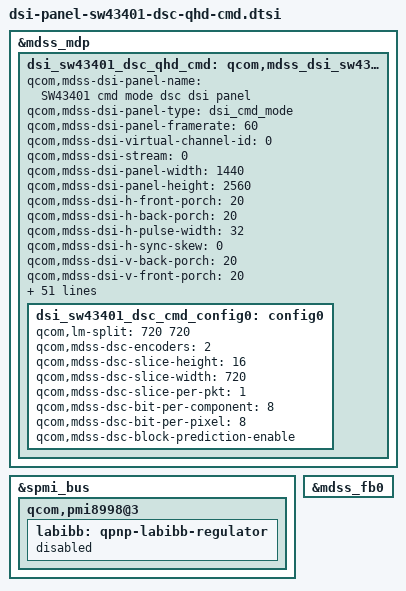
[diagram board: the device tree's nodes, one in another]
/* Copyright (c) 2017, The Linux Foundation. All rights reserved.
 *
 * This program is free software; you can redistribute it and/or modify
 * it under the terms of the GNU General Public License version 2 and
 * only version 2 as published by the Free Software Foundation.
 *
 * This program is distributed in the hope that it will be useful,
 * but WITHOUT ANY WARRANTY; without even the implied warranty of
 * MERCHANTABILITY or FITNESS FOR A PARTICULAR PURPOSE.  See the
 * GNU General Public License for more details.
 */

&mdss_mdp {
	dsi_sw43401_dsc_qhd_cmd: qcom,mdss_dsi_sw43401_dsc_qhd_cmd {
		qcom,mdss-dsi-panel-name = "SW43401 cmd mode dsc dsi panel";
		qcom,mdss-dsi-panel-type = "dsi_cmd_mode";
		qcom,mdss-dsi-panel-framerate = <60>;
		qcom,mdss-dsi-virtual-channel-id = <0>;
		qcom,mdss-dsi-stream = <0>;
		qcom,mdss-dsi-panel-width = <1440>;
		qcom,mdss-dsi-panel-height = <2560>;
		qcom,mdss-dsi-h-front-porch = <20>;
		qcom,mdss-dsi-h-back-porch = <20>;
		qcom,mdss-dsi-h-pulse-width = <32>;
		qcom,mdss-dsi-h-sync-skew = <0>;
		qcom,mdss-dsi-v-back-porch = <20>;
		qcom,mdss-dsi-v-front-porch = <20>; //180 -> 100
		qcom,mdss-dsi-v-pulse-width = <6>;
		qcom,mdss-dsi-h-left-border = <0>;
		qcom,mdss-dsi-h-right-border = <0>;
		qcom,mdss-dsi-v-top-border = <0>;
		qcom,mdss-dsi-v-bottom-border = <0>;
		qcom,mdss-dsi-bpp = <24>;
		qcom,mdss-dsi-color-order = "rgb_swap_rgb";
		qcom,mdss-dsi-underflow-color = <0xff>;
		qcom,mdss-dsi-border-color = <0>;
		qcom,mdss-dsi-h-sync-pulse = <0>;
		qcom,mdss-dsi-traffic-mode = "burst_mode";
		qcom,mdss-dsi-lane-map = "lane_map_0123";
		qcom,mdss-dsi-bllp-eof-power-mode;
		qcom,mdss-dsi-bllp-power-mode;
		/* qcom,partial-update-enabled; */
		/* qcom,panel-roi-alignment = <1440 16 1440 16 1440 16>; */
		qcom,mdss-dsi-lane-0-state;
		qcom,mdss-dsi-lane-1-state;
		qcom,mdss-dsi-lane-2-state;
		qcom,mdss-dsi-lane-3-state;
		qcom,mdss-dsi-reset-sequence = <1 10>, <0 10>, <1 10>;
		qcom,mdss-dsi-dma-trigger = "trigger_sw";
		qcom,mdss-dsi-mdp-trigger = "none";
		qcom,mdss-dsi-te-pin-select = <1>;
		qcom,mdss-dsi-wr-mem-start = <0x2c>;
		qcom,mdss-dsi-wr-mem-continue = <0x3c>;
		qcom,mdss-dsi-te-dcs-command = <1>;
		qcom,mdss-dsi-te-check-enable;
		qcom,mdss-dsi-te-using-te-pin;
		qcom,mdss-dsi-lp11-init;
		qcom,mdss-dsi-tx-eot-append;
		qcom,mdss-mdp-transfer-time-us = <15000>;
		qcom,ulps-enabled;
		qcom,mdss-dsi-force-clock-lane-hs = <1>;
		qcom,mdss-dsi-panel-orientation = "vflip";

		qcom,mdss-dsi-on-command = [
			15 01 00 00 00 00 02 B0 5A
			15 01 00 00 00 00 02 51 00
			15 01 00 00 00 00 02 53 20
			15 01 00 00 01 00 02 55 0C
			39 01 00 00 00 00 07 B1 AA 00 4A 14 14 14
			39 01 00 00 00 00 0C B2 3D 41 02 80 FF FF 15 00 00 00 00
			39 01 00 00 00 00 0E B4 21 12 81 00 FF 00 78 00 FF 80 00 C2 02
			39 01 00 00 00 00 0E B5 9A 80 00 A0 05 00 0A D0 02 10 00 D0 02
			39 01 00 00 00 00 0E B6 84 01 0A F0 20 00 08 C5 04 00 18 F0 10
			39 01 00 00 01 00 0B B7 03 A6 06 00 88 08 88 88 88 00
			39 01 00 00 00 00 0D B8 3F 20 20 20 20 3F 00 00 40 80 00 11
			39 01 00 00 00 00 09 B9 D7 CA AB 8F 73 57 25 1B
			39 01 00 00 00 00 19 BA 00 66 DA DB D6 CC D5 D6 00 50 E4 DD D8 CB D5 D5 00 93 DF D7 D1 C8 D1 D2
			15 01 00 00 01 00 02 51 00
			39 01 00 00 00 00 05 E0 00 00 F8 80
			39 01 00 00 00 00 08 E1 00 C0 00 80 00 00 00
			39 01 00 00 00 00 0A E2 0A D2 F4 83 83 83 5C 5C 5C
			39 01 00 00 00 00 08 E3 9D EB E0 AA 2A AA B8
			39 01 00 00 00 00 04 E4 51 48 34
			39 01 00 00 00 00 07 E5 F7 E1 01 43 33 03
			39 01 00 00 00 00 0F E6 55 55 00 13 42 A0 0A 0B 00 0A 0B F0 05 0B
			39 01 00 00 00 00 09 E7 1F 1F 3F FF 00 1F 4A 00
			39 01 00 00 00 00 06 D4 01 8E 00 21 05
			39 01 00 00 00 00 0B D7 00 28 28 28 28 28 28 28 28 28
			39 01 00 00 00 00 02 36 02
			05 01 00 00 00 00 01 11
			05 01 00 00 00 00 01 35
			15 01 00 00 78 00 02 FA 13
			39 01 00 00 00 00 06 F3 13 05 00 00 31
			39 01 00 00 00 00 04 F8 00 00 11
			15 01 00 00 00 00 02 F9 80
			];
		qcom,mdss-dsi-on-command-state = "dsi_lp_mode";

		qcom,mdss-dsi-post-panel-on-command = [
			05 01 00 00 00 00 01 29
			];

		qcom,mdss-dsi-off-command = [
			/* Display Off */
			05 01 00 00 00 00 01 28
			/* Sleep In + min 90ms */
			05 01 00 00 5A 00 01 10
		];
		qcom,mdss-dsi-off-command-state = "dsi_lp_mode";

		lge,blmap = <
				0
				1 2 3 4 5 6 7 8 9 10
				11 12 13 14 15 16 17 18 19 20
				21 22 23 24 25 26 27 28 29 30
				31 32 33 34 35 36 37 38 39 40
				41 42 43 44 45 46 47 48 49 50
				51 52 53 54 55 56 57 58 59 60
				71 72 73 74 75 75 77 78 79 80
				81 82 83 84 85 86 87 88 89 90
				91 92 93 94 95 96 97 98 99 100
				101 102	103 104	105 106	107 108	109 110
				111 112	113 114	115 116	117 118	119 120
				121 122	123 124	125 126	127 128	129 130
				131 132	133 134	135 136	137 138	139 140
				141 142	143 144	145 146	147 148	149 150
				151 152	153 154	155 156	157 158	159 160
				161 162	163 164	165 166	167 168	169 170
				171 172	173 174	175 176	177 178	179 180
				181 182	183 184	185 186	187 188	189 190
				191 192	193 194	195 196	197 198	199 200
				201 202	203 204	205 206	207 208	209 210
				211 212	213 214	215 216	217 218	219 220
				221 222	223 224	225 226	227 228	229 230
				231 232	233 234	235 236	237 238	239 240
				241 242	243 244	245 246	247 248	249 250
				251 252	253 254	255
		>;

		qcom,mode-control-dsi-state = "dsi_lp_mode";
		qcom,mdss-pan-physical-width-dimension = <68>;
		qcom,mdss-pan-physical-height-dimension = <121>;

		qcom,compression-mode = "dsc";
		qcom,config-select = <&dsi_sw43401_dsc_cmd_config0>;

		qcom,mdss-dsc-version = <0x11>;
		qcom,mdss-dsc-scr-version = <0x1>;

		dsi_sw43401_dsc_cmd_config0: config0 {
			qcom,lm-split = <720 720>;
			qcom,mdss-dsc-encoders = <2>;
			qcom,mdss-dsc-slice-height = <16>;
			qcom,mdss-dsc-slice-width = <720>;
			qcom,mdss-dsc-slice-per-pkt = <1>;

			qcom,mdss-dsc-bit-per-component = <8>;
			qcom,mdss-dsc-bit-per-pixel = <8>;
			qcom,mdss-dsc-block-prediction-enable;
		};
	};
};

&spmi_bus {
	qcom,pmi8998@3 {
		labibb: qpnp-labibb-regulator {
			status = "disabled";
		};
	};
};

&mdss_fb0 {
	/delete-node/ qcom,cont-splash-memory;
};
